# SIBG301M104LGL register map
Vendor: Silicon Labs; Series: Si; File version: B
Registers are 32-bit, read-write, reset 0x0 unless marked. A register's access mark holds for its fields unless they carry their own. Offsets are from the block's base; [hi:lo] are bit positions; {n}, {i} and the like mark numbered series.

## GPCRC0_NS — GPCRC0_NS Registers
Base 0x4087C000
Same registers: GPCRC0_S 0x5087C000
0x00 IPVERSION ro
0x04 EN
  [0] EN — CRC Enable
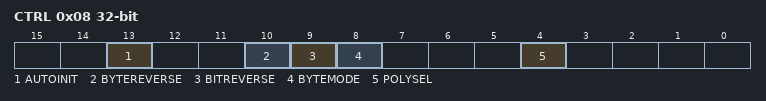
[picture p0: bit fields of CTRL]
0x08 CTRL
  [13] AUTOINIT — Auto Init Enable
  [10] BYTEREVERSE — Byte Reverse Mode
    0=NORMAL (No reverse: B3, B2, B1, B0); 1=REVERSED (Reverse byte order. For 32-bit: B0, B1, B2, B3; For 16-bit: 0, 0, B0, B1)
  [9] BITREVERSE — Byte-level Bit Reverse Enable
    0=NORMAL (No reverse); 1=REVERSED (Reverse bit order in each byte)
  [8] BYTEMODE — Byte Mode Enable
  [4] POLYSEL — Polynomial Select
    0=CRC32 (CRC-32 (0x04C11DB7) polynomial selected); 1=CRC16 (16-bit CRC programmable polynomial selected)
0x0C CMD wo
  [0] INIT — Initialization Enable
0x10 INIT
  [31:0] INIT — CRC Initialization Value
0x14 POLY
  [15:0] POLY — CRC Polynomial Value
0x18 INPUTDATA wo
  [31:0] INPUTDATA — Input Data for 32-bit
0x1C INPUTDATAHWORD wo
  [15:0] INPUTDATAHWORD — Input Data for 16-bit
0x20 INPUTDATABYTE wo
  [7:0] INPUTDATABYTE — Input Data for 8-bit
0x24 DATA ro
  [31:0] DATA — CRC Data Register
0x28 DATAREV ro
  [31:0] DATAREV — Data Reverse Value
0x2C DATABYTEREV ro
  [31:0] DATABYTEREV — Data Byte Reverse Value

## HFRCO0_NS — HFRCO0_NS Registers
Base 0x40810000
Same registers: HFRCOEM23_NS 0x40100000, HFRCOEM23_S 0x50100000, HFRCO0_S 0x50810000
0x00 IPVERSION ro reset 0x3
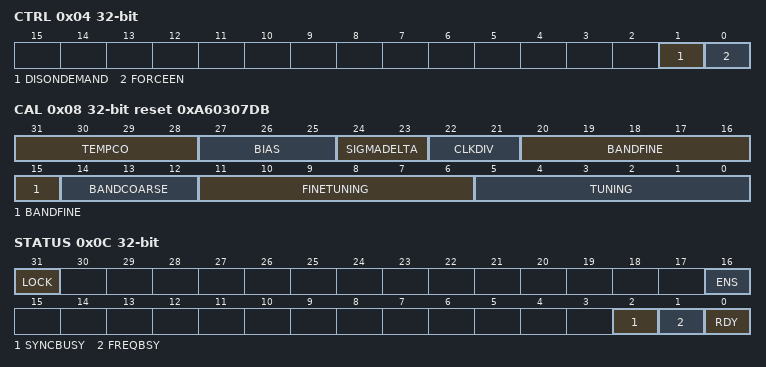
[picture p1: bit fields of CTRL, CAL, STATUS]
0x04 CTRL
  [1] DISONDEMAND — Disable On-demand
  [0] FORCEEN — Force Enable
0x08 CAL reset 0xA60307DB
  [31:28] TEMPCO — Tempco Trim
  [27:25] BIAS — Bias Current Setting
  [24:23] SIGMADELTA — Sigma Delta Setting
  [22:21] CLKDIV — Locally Divide HFRCO Clock Output
    0=DIV1 (Divide by 1.); 1=DIV2 (Divide by 2.); 2=DIV4 (Divide by 4.); 3=DIV8 (Divide by 8)
  [20:15] BANDFINE — Band Fine Value
  [14:12] BANDCOARSE — Band Coarse Value
  [11:6] FINETUNING — Fine Tuning Value
  [5:0] TUNING — Coarse Tuning Value
0x0C STATUS ro
  [31] LOCK — Lock Status
    0=UNLOCKED (HFRCO is unlocked); 1=LOCKED (HFRCO is locked)
  [16] ENS — Enable Status
  [2] SYNCBUSY — Synchronization Busy
  [1] FREQBSY — Frequency Updating Busy
  [0] RDY — Ready
0x10 IF
  [0] RDY — Ready Interrupt Flag
0x14 IEN
  [0] RDY — RDY Interrupt Enable
0x1C LOCK wo reset 0x8195
  [15:0] LOCKKEY
    0x8195=UNLOCK (Unlock code)

## HOSTPORTAL_NS — HOSTPORTAL_NS Registers
Base 0xA3018000
Same registers: HOSTPORTAL_S 0xB3018000
0x00 IPID ro reset 0x1
  [31:0] IPVERSION — IP version ID
0x04 CTRL
  [0] LPW0PWRUPREQ — LPW0 Power Up Request
0x08 STATUS
  [0] LPW0PWRUPACK — LPW0 Power up status
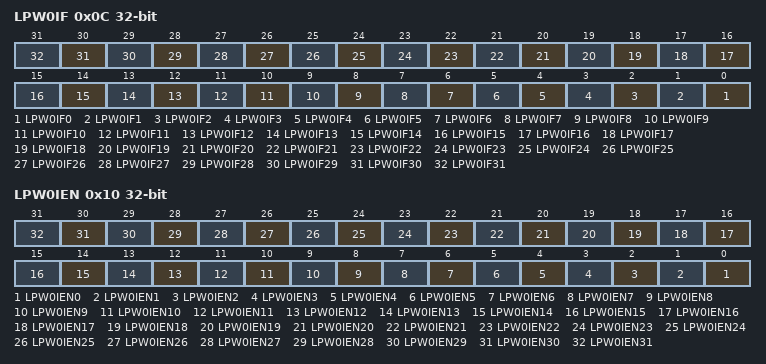
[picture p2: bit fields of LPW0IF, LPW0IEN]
0x0C LPW0IF
  [n] LPW0IF{n} (n=0..31) — Interrupt Flag Register
0x10 LPW0IEN
  [n] LPW0IEN{n} (n=0..31) — Interrupt Enable Register
{0x14+4i} MAILBOXREG{i} (i=0..7)
  [31:0] MESSAGE — MB message

## LPW0PORTAL_NS — LPW0PORTAL_NS Registers
Base 0xA3014000
Same registers: LPW0PORTAL_S 0xB3014000
Registers as HOSTPORTAL_NS, without LPW0IF, LPW0IEN; these are added or differ:
0x04 CTRL
  [0] HOSTPWRUPREQ — HOST Power Up Request
0x08 STATUS ro
  [0] HOSTPWRUPACK — Host Power up status
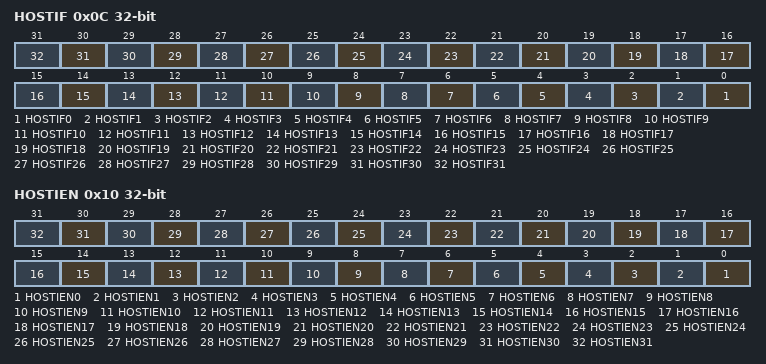
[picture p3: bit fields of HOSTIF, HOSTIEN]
0x0C HOSTIF
  [n] HOSTIF{n} (n=0..31) — Interrupt Flag Register
0x10 HOSTIEN
  [n] HOSTIEN{n} (n=0..31) — Interrupt Enable Register

## KSU_NS — KSU_NS Registers
Base 0x4089C000
Same registers: KSU_S 0x5089C000
0x00 IPVERSION ro reset 0x1
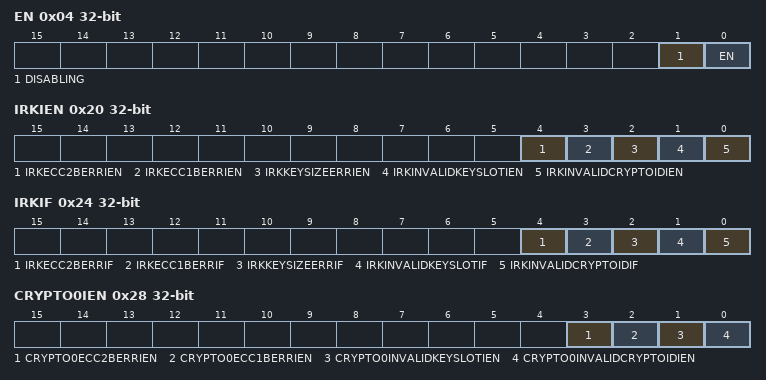
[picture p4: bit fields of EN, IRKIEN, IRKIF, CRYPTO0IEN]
0x04 EN
  [1] DISABLING ro — KSU Disable
  [0] EN — KSU Enable
0x08 CTRL
  [0] RETNCTRL — enable of retention control
0x0C IRKCMD wo
  [0] CLEARECC — clear the error slots of DKP0
0x10 CRYPTO0CMD wo
  [0] CLEARECC — clears the error slots for DKP0
0x14 CRYPTO1CMD wo
  [0] CLEARECC — clears the error slot of DKP1
0x18 INFO
  [0] SETUPDONE — Handshake bit for SE and USER
0x1C STATUS ro
  [0] KEYREQLOCKACK — Key request stall
0x20 IRKIEN
  [4] IRKECC2BERRIEN — ECC 2b error for IRK interface
  [3] IRKECC1BERRIEN — ECC 1b error for IRK interface
  [2] IRKKEYSIZEERRIEN — rpa keysize err
  [1] IRKINVALIDKEYSLOTIEN — rpa slotid err
  [0] IRKINVALIDCRYPTOIDIEN — rpa engineid err
0x24 IRKIF
  [4] IRKECC2BERRIF — ECC error 2b IRK intf
  [3] IRKECC1BERRIF — Ecc error 1b IRK intf
  [2] IRKKEYSIZEERRIF — rpa keysize err flag
  [1] IRKINVALIDKEYSLOTIF — rpa slotid err flag
  [0] IRKINVALIDCRYPTOIDIF — rpa engineid err flag
0x28 CRYPTO0IEN
  [3] CRYPTO0ECC2BERRIEN — ECC 2b error crypto int 0
  [2] CRYPTO0ECC1BERRIEN — ECC 1b error crypto int 0
  [1] CRYPTO0INVALIDKEYSLOTIEN — DKP_IF0 slot id error
  [0] CRYPTO0INVALIDCRYPTOIDIEN — DKP_IF0 engine id error
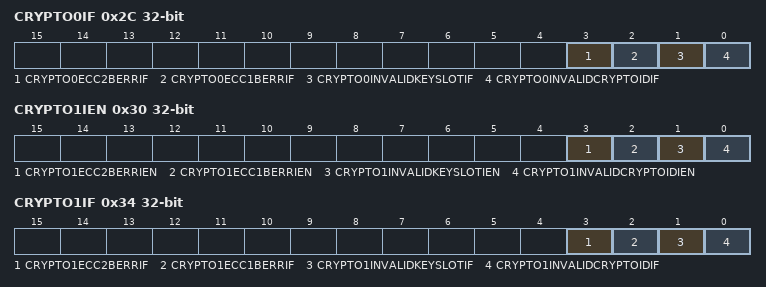
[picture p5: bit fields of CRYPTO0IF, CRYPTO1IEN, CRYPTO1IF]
0x2C CRYPTO0IF
  [3] CRYPTO0ECC2BERRIF — ECC error 2b crypto intf0
  [2] CRYPTO0ECC1BERRIF — Ecc error 1b crypto intf0
  [1] CRYPTO0INVALIDKEYSLOTIF — DKP_IF0 slotid error flag
  [0] CRYPTO0INVALIDCRYPTOIDIF — DKP_IF0 engineid error flag
0x30 CRYPTO1IEN
  [3] CRYPTO1ECC2BERRIEN — ECC 2b error crypto int 0
  [2] CRYPTO1ECC1BERRIEN — ECC 1b error crypto int 0
  [1] CRYPTO1INVALIDKEYSLOTIEN — DKP_IF1 slot id error
  [0] CRYPTO1INVALIDCRYPTOIDIEN — DKP_IF1 engine id error
0x34 CRYPTO1IF
  [3] CRYPTO1ECC2BERRIF — ECC error 2b crypto intf0
  [2] CRYPTO1ECC1BERRIF — Ecc error 1b crypto intf0
  [1] CRYPTO1INVALIDKEYSLOTIF — DKP_IF1 slotid error flag
  [0] CRYPTO1INVALIDCRYPTOIDIF — DKP_IF1 engineid error flag
0x38 IRKECCERRKEYSLOT ro
  [7:0] IRKECCERRKEYSLOT — ecc error slot id for CPU1
0x3C CRYPTO0ECCERRKEYSLOT ro
  [7:0] CRYPTO0ECCERRKEYSLOT — ECC KEY SLOT ID error DKP0 for CPU1
0x40 CRYPTO1ECCERRKEYSLOT ro
  [7:0] CRYPTO1ECCERRKEYSLOT — ECC KEY SLOT ID error DKP1
0x44 CORERESET wo
  [0] CORERESET — resets the ksu
0x48 MISC reset 0x7
  [2:0] SWAP — swap the key order
